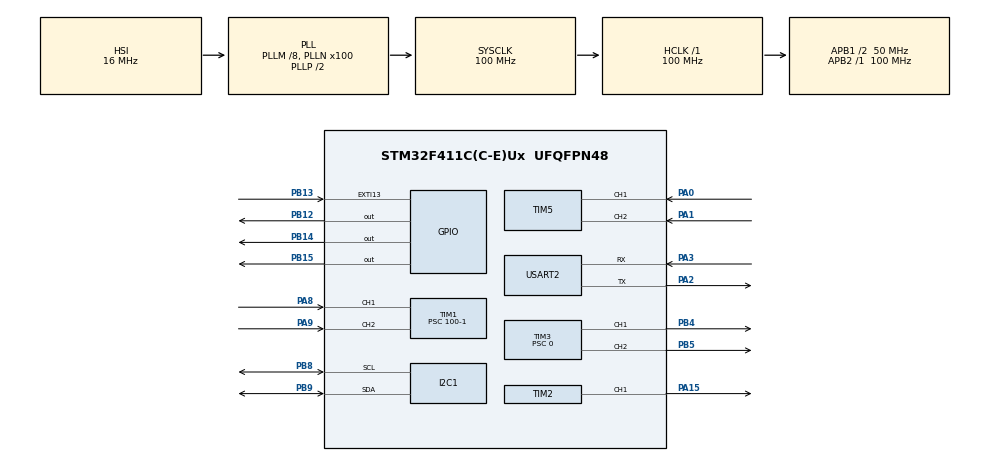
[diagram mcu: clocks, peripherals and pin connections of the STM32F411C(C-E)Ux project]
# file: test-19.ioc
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Mcu.Family=STM32F4
Mcu.Name=STM32F411C(C-E)Ux
Mcu.Package=UFQFPN48
NVIC.EXTI15_10_IRQn=true\:0\:0\:false\:false\:true\:true\:true\:true
NVIC.PriorityGroup=NVIC_PRIORITYGROUP_4
NVIC.TIM1_BRK_TIM9_IRQn=true\:0\:0\:false\:false\:true\:true\:true\:true
NVIC.TIM1_CC_IRQn=true\:0\:0\:false\:false\:true\:true\:true\:true
NVIC.TIM1_TRG_COM_TIM11_IRQn=true\:0\:0\:false\:false\:true\:true\:true\:true
NVIC.TIM1_UP_TIM10_IRQn=true\:0\:0\:false\:false\:true\:true\:true\:true
NVIC.TIM5_IRQn=true\:0\:0\:false\:false\:true\:true\:true\:true
PA0-WKUP.Signal=S_TIM5_CH1
PA1.Signal=S_TIM5_CH2
PA13.Mode=Trace_Asynchronous_SW
PA13.Signal=SYS_JTMS-SWDIO
PA14.Mode=Trace_Asynchronous_SW
PA14.Signal=SYS_JTCK-SWCLK
PA15.Signal=S_TIM2_CH1_ETR
PA2.Mode=Asynchronous
PA2.Signal=USART2_TX
PA3.Mode=Asynchronous
PA3.Signal=USART2_RX
PA8.Signal=S_TIM1_CH1
PA9.Signal=S_TIM1_CH2
PB12.Signal=GPIO_Output
PB13.Signal=GPXTI13
PB14.Signal=GPIO_Output
PB15.Signal=GPIO_Output
PB3.Mode=Trace_Asynchronous_SW
PB3.Signal=SYS_JTDO-SWO
PB4.Signal=S_TIM3_CH1
PB5.Signal=S_TIM3_CH2
PB8.Mode=I2C
PB8.Signal=I2C1_SCL
PB9.Mode=I2C
PB9.Signal=I2C1_SDA
ProjectManager.HeapSize=0x200
ProjectManager.StackSize=0x400
ProjectManager.TargetToolchain=STM32CubeIDE
RCC.48MHZClocksFreq_Value=50000000
RCC.AHBFreq_Value=100000000
RCC.APB1CLKDivider=RCC_HCLK_DIV2
RCC.APB1Freq_Value=50000000
RCC.APB1TimFreq_Value=100000000
RCC.APB2Freq_Value=100000000
RCC.APB2TimFreq_Value=100000000
RCC.CortexFreq_Value=100000000
RCC.HCLKFreq_Value=100000000
RCC.HSE_VALUE=25000000
RCC.HSI_VALUE=16000000
RCC.LSE_VALUE=32768
RCC.PLLM=8
RCC.PLLN=100
RCC.SYSCLKFreq_VALUE=100000000
RCC.SYSCLKSource=RCC_SYSCLKSOURCE_PLLCLK
RCC.VCOOutputFreq_Value=200000000
SH.S_TIM1_CH1.0=TIM1_CH1,Input_Capture1_from_TI1
SH.S_TIM1_CH2.0=TIM1_CH2,Input_Capture2_from_TI2
SH.S_TIM2_CH1_ETR.0=TIM2_CH1,PWM Generation1 CH1
SH.S_TIM3_CH1.0=TIM3_CH1,PWM Generation1 CH1
SH.S_TIM3_CH2.0=TIM3_CH2,PWM Generation2 CH2
SH.S_TIM5_CH1.0=TIM5_CH1,Encoder_Interface
SH.S_TIM5_CH2.0=TIM5_CH2,Encoder_Interface
TIM1.Channel-Input_Capture1_from_TI1=TIM_CHANNEL_1
TIM1.Channel-Input_Capture2_from_TI2=TIM_CHANNEL_2
TIM1.ICPolarity_CH1=TIM_INPUTCHANNELPOLARITY_BOTHEDGE
TIM1.ICPolarity_CH2=TIM_INPUTCHANNELPOLARITY_BOTHEDGE
TIM1.Prescaler=100-1
TIM2.Channel-PWM\ Generation1\ CH1=TIM_CHANNEL_1
TIM2.Period=5000-1
TIM3.Channel-PWM\ Generation1\ CH1=TIM_CHANNEL_1
TIM3.Channel-PWM\ Generation2\ CH2=TIM_CHANNEL_2
TIM3.Period=5000-1
TIM3.Prescaler=0
TIM5.EncoderMode=TIM_ENCODERMODE_TI12
USART2.VirtualMode=VM_ASYNC
VP_TIM1_VS_ClockSourceINT.Mode=Internal
VP_TIM2_VS_ClockSourceINT.Mode=Internal
VP_TIM3_VS_ClockSourceINT.Mode=Internal
board=custom

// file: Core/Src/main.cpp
/* USER CODE BEGIN Header */
/**
  ******************************************************************************
  * @file           : main.c
  * @brief          : Main program body
  ******************************************************************************
  * @attention
  *
  * Copyright (c) 2024 STMicroelectronics.
  * All rights reserved.
  *
  * This software is licensed under terms that can be found in the LICENSE file
  * in the root directory of this software component.
  * If no LICENSE file comes with this software, it is provided AS-IS.
  *
  ******************************************************************************
  */
/* USER CODE END Header */
#include "main.h"

/* USER CODE BEGIN Includes */
#include <stdio.h>
#include <cmath>
#include "defines.h"
#include "vl53l0x_api.h"
#include "TB6612FNG_Motor.h"
#include "RCChannel.h"
#include "RemoteControlControl.h"
#include "PololuEncoder.h"
#include "MotorControl.h"
#include "PololuServo.h"
#include "VL53L0X.h"
#include "SparkFunAPDS9960.h"
#include "ConveyorBelt.h"
#include "ColoredBlock.h"

/* USER CODE END Includes */

/* USER CODE BEGIN PD */
#define CPU_CLOCK_SPEED_MHZ 100
#define MOTOR_PWM_HZ 20000
#define RC_SIGNAL_PERIOD_US 17500
#define CONTROL_FREQUENCY_HZ 8
/* USER CODE END PD */

I2C_HandleTypeDef hi2c1;

TIM_HandleTypeDef htim1;
TIM_HandleTypeDef htim2;
TIM_HandleTypeDef htim3;
TIM_HandleTypeDef htim5;

UART_HandleTypeDef huart2;

/* USER CODE BEGIN PV */
char my_message[MESSAGE_LENGTH] = "";
int string_length;
bool initialized = false;
TB6612FNG_Motor* My_Motor;
RCChannel* ThrottleChannel;
RCChannel* SteeringChannel;
RemoteControlControl* Throttle;
RemoteControlControl* Steering;
PololuEncoder* My_Encoder;
MotorControl* My_Controller;
PololuServo* My_Servo;
//VL53L0X* My_ToF_Sensor;
VL53L0X_RangingMeasurementData_t RangingData;
VL53L0X_Dev_t vl53l0x_c; // center module
VL53L0X_DEV Dev = &vl53l0x_c;
ConveyorBelt* My_Conveyor;
SparkFun_APDS9960* My_Color_Sensor;
ColoredBlock* My_Block;
/* USER CODE END PV */

void SystemClock_Config(void);
static void MX_GPIO_Init(void);
static void MX_USART2_UART_Init(void);
static void MX_TIM2_Init(void);
static void MX_TIM5_Init(void);
static void MX_TIM1_Init(void);
static void MX_TIM3_Init(void);
static void MX_I2C1_Init(void);
/* USER CODE BEGIN PFP */
static void VL53L0X_Init(void);
void I2C_Scan(UART_HandleTypeDef* uart_handle);
/* USER CODE END PFP */

/* USER CODE BEGIN 0 */
void HAL_GPIO_EXTI_Callback(uint16_t GPIO_PIN) {
   // Your interrupt handling code here
	if(initialized)
	{
		if(GPIO_PIN == GPIO_PIN_13)
		{
			HAL_GPIO_TogglePin(GPIOB, GPIO_PIN_12);
		}
	}
}

void HAL_TIM_IC_CaptureCallback(TIM_HandleTypeDef *htim)
{
	if (initialized) // Timers must be initalized before this code can run successfully.
	{
		if((htim->Instance = TIM1))
		{
			if ( htim->Channel == HAL_TIM_ACTIVE_CHANNEL_1 )
			{
				SteeringChannel->callback();
			}

			if ( htim->Channel == HAL_TIM_ACTIVE_CHANNEL_2)
			{
				ThrottleChannel->callback();
			}
		}
	}
}

void HAL_TIM_PeriodElapsedCallback(TIM_HandleTypeDef *htim) // Not needed
{
	if (htim->Instance == TIM5)
	{
		My_Encoder->count = __HAL_TIM_GET_COUNTER(htim);
	}
}
/* USER CODE END 0 */

int main(void)
{

  /* MCU Configuration--------------------------------------------------------*/

  /* Reset of all peripherals, Initializes the Flash interface and the Systick. */
  HAL_Init();

  /* Configure the system clock */
  SystemClock_Config();

  /* Initialize all configured peripherals */
  MX_GPIO_Init();
  MX_USART2_UART_Init();
  MX_TIM2_Init();
  MX_TIM5_Init();
  MX_TIM1_Init();
  MX_TIM3_Init();
  MX_I2C1_Init();
  /* USER CODE BEGIN 2 */
  My_Motor = new TB6612FNG_Motor
		  (
		  GPIOB, GPIO_PIN_14,
		  GPIOB, GPIO_PIN_15,
		  &htim2, TIM_CHANNEL_1,
		  CPU_CLOCK_SPEED_MHZ,
		  MOTOR_PWM_HZ
		  );

  SteeringChannel = new RCChannel
		  (
		  GPIOA,
		  GPIO_PIN_8,
  		  &htim1,
  		  TIM_CHANNEL_1,
  		  RC_SIGNAL_PERIOD_US,
  		  CPU_CLOCK_SPEED_MHZ,
  		  1002,       // Calibrated full right
  		  1520,      // Calibrated neutral
  		  2035,      // Calibrated full left
  		  10000,       // New max positive
		  10000,       // New max negative (magnitude)
		  true     // Saturate if signal is over full? True by default. False good for debugging.
		  );

  ThrottleChannel = new RCChannel
		  	  	  (
		  	  	  GPIOA,
				  GPIO_PIN_9,
		  		  &htim1,
		  		  TIM_CHANNEL_2,
		  		  RC_SIGNAL_PERIOD_US,
		  		  CPU_CLOCK_SPEED_MHZ,
		  		  1056,  // Calibrated full reverse
		  		  1533,  // Calibrated neutral
		  		  2017,  // Calibrated full speed
		  		  10000,   // New max positive
				  10000,    // New max negative (magnitude)
				  true  // Saturate if signal is over full? True by default. False good for debugging.
		  	  	  );

  My_Encoder = new PololuEncoder
		  (
		  &htim5,
		  20,
		  488.3f,
		  16,
		  false // true doesn't work yet!
		  );

  My_Controller = new MotorControl
		  (
		  My_Motor,
		  My_Encoder,
		  CONTROL_FREQUENCY_HZ,
		  100.0f,
		  650.0f,
		  0.0f
		  );

  Throttle = new RemoteControlControl
		  (
		  ThrottleChannel,
		  My_Controller,
		  30
		  );

  My_Servo = new PololuServo
		  (
		  &htim3,
		  TIM_CHANNEL_1,
		  17500,
	  	  CPU_CLOCK_SPEED_MHZ,
		  60,
		  1000,
		  1500,
		  2000
		  );

//  My_ToF_Sensor = new VL53L0X
//		  (
//		  &hi2c1,
//		  0x29
//		  );

  My_Conveyor = new ConveyorBelt(My_Encoder, 38.1f);

  // Not shutdown pin for ToF_Sensor
  HAL_GPIO_WritePin(GPIOB, GPIO_PIN_10, GPIO_PIN_SET);
  VL53L0X_Init();

  // Color sensor
  My_Color_Sensor = new SparkFun_APDS9960(&hi2c1);
  //I2C_Scan(&huart2);

  My_Color_Sensor->init();
  My_Color_Sensor->disableProximitySensor();
  My_Color_Sensor->disableGestureSensor();
  My_Color_Sensor->enableLightSensor();
//  if (My_Color_Sensor->init()) {
//      int string_length = sprintf(my_message, "My_Color_Sensor-9960 initialization complete\r\n");
//      HAL_UART_Transmit(&huart2, (uint8_t *)my_message, string_length, HAL_MAX_DELAY);
//  } else {
//      int string_length = sprintf(my_message, "Something went wrong during My_Color_Sensor-9960 init!\r\n");
//      HAL_UART_Transmit(&huart2, (uint8_t *)my_message, string_length, HAL_MAX_DELAY);
//  }
//
//  I2C_Scan(&huart2);
//  if (My_Color_Sensor->disableProximitySensor()) {
//      int string_length = sprintf(my_message, "Proximity sensor disabled successfully\r\n");
//      HAL_UART_Transmit(&huart2, (uint8_t *)my_message, string_length, HAL_MAX_DELAY);
//  } else {
//      int string_length = sprintf(my_message, "Failed to disable proximity sensor\r\n");
//      HAL_UART_Transmit(&huart2, (uint8_t *)my_message, string_length, HAL_MAX_DELAY);
//  }
//
//  if (My_Color_Sensor->disableGestureSensor()) {
//      int string_length = sprintf(my_message, "Gesture sensor disabled successfully\r\n");
//      HAL_UART_Transmit(&huart2, (uint8_t *)my_message, string_length, HAL_MAX_DELAY);
//  } else {
//      int string_length = sprintf(my_message, "Failed to disable gesture sensor\r\n");
//      HAL_UART_Transmit(&huart2, (uint8_t *)my_message, string_length, HAL_MAX_DELAY);
//  }
//
//  if (My_Color_Sensor->enableLightSensor()) {
//      int string_length = sprintf(my_message, "Light sensor enabled successfully\r\n");
//      HAL_UART_Transmit(&huart2, (uint8_t *)my_message, string_length, HAL_MAX_DELAY);
//  } else {
//      int string_length = sprintf(my_message, "Failed to enable light sensor\r\n");
//      HAL_UART_Transmit(&huart2, (uint8_t *)my_message, string_length, HAL_MAX_DELAY);
//  }
//  I2C_Scan(&huart2);

  uint16_t ambient_light, red_light, green_light, blue_light;

  uint8_t task = 0; // Start on task 0
  int number_of_states = 5;

  number_of_states += 1;
  uint32_t last_tick_state[number_of_states] = {0};
  uint16_t task_frequencies[number_of_states] = {0};
  task_frequencies[1] = CONTROL_FREQUENCY_HZ; // Hz
  task_frequencies[2] = 2; // Hz
  task_frequencies[3] = 10; // Hz
  task_frequencies[4] = 2; // Hz
  uint16_t task_periods[number_of_states] = {0};

  // Loop to calculate periods based on frequencies
  for (int index = 0; index < number_of_states; index++) {
      if (task_frequencies[index] != 0) {
          task_periods[index] = 1000 / task_frequencies[index];
      } else {
          task_periods[index] = 0; // Avoid division by zero
      }
  }

  uint16_t range_reading = -1;
  uint16_t block_range_mm = 50; //Threshold
  float distance_from_ToF_to_color_sensor = 42.0f;
  bool ready_for_new_block = true;
  float first_position;
  float second_position;
  /* USER CODE END 2 */

  /* Infinite loop */
  while (1)
  {

    /* USER CODE BEGIN 3 */
	  uint32_t current_tick = HAL_GetTick();

	  switch(task)
	  {
	  	  case 0:
	  		  // Init
	  		  My_Servo->set_position(0);
	  		  HAL_Delay(300);
	  		  My_Controller->run(0);
	  		  My_Servo->set_position(0);
	  		  HAL_Delay(500);
	  		  initialized = true;

	  		  // State change
	  		  task = 1;
	  		  break;

	  	  case 1: // Motor Controller
	  		  if (current_tick - last_tick_state[1] >= task_periods[1])
	  		  {
	  			  last_tick_state[1] = current_tick;
	  			  //Throttle->update_motor();

		  		  // Set speed
		  		  My_Controller->run(-15); // RPM
	  		  }

	  		  // State change
	  		  task = 2;
	  		  break;

	  	  case 2: // ToF Sensor
			  if (current_tick - last_tick_state[2] >= task_periods[2])
			  {
				  last_tick_state[2] = current_tick;
				  //range_reading = My_ToF_Sensor->read(&huart2, true);

				  VL53L0X_PerformSingleRangingMeasurement(Dev, &RangingData);
//					if(RangingData.RangeStatus == 0) {
//						int string_length = sprintf(my_message, "Measured distance: %i\n\r", RangingData.RangeMilliMeter);
//						HAL_UART_Transmit(&huart2, (uint8_t*)my_message, string_length, HAL_MAX_DELAY);
//					} else {
//						int string_length = sprintf(my_message, "Error\r\n");
//						HAL_UART_Transmit(&huart2, (uint8_t*)my_message, string_length, HAL_MAX_DELAY);
//					}

					if(ready_for_new_block)
					{

						if(RangingData.RangeMilliMeter <= block_range_mm)
						{
							// Debug message
							int string_length = sprintf(my_message, "A block was found\r\n");
							HAL_UART_Transmit(&huart2, (uint8_t *)my_message, string_length, HAL_MAX_DELAY);

							// Store the current encoder posiiton for later.
							first_position = My_Conveyor->get_position();
							string_length = sprintf(my_message, "Block position: %.3f mm.\r\n", first_position);
							HAL_UART_Transmit(&huart2, (uint8_t *)my_message, string_length, HAL_MAX_DELAY);

							// Stop checking for blocks.
							ready_for_new_block = false;

							// Create a new block instance
							My_Block = new ColoredBlock(My_Conveyor);
						}
					}
			  }

			  // State Changes
			  task = 3;
			  break;

	  	  case 3: // Color Sensor
			  if (current_tick - last_tick_state[3] >= task_periods[3])
			  {
				  last_tick_state[3] = current_tick;

				  if (not ready_for_new_block)
				  {
					  // Debug message
					  second_position = My_Conveyor->get_position();
					  int string_length = sprintf(my_message, "Block position: %.2f mm.\r\n", fabs(second_position-first_position));
					  HAL_UART_Transmit(&huart2, (uint8_t *)my_message, string_length, HAL_MAX_DELAY);

					  if (fabs(second_position-first_position) >= distance_from_ToF_to_color_sensor)
					  {
						   // Debug message
							string_length = sprintf(my_message, "Block has reached color sensor \r\n");
							HAL_UART_Transmit(&huart2, (uint8_t *)my_message, string_length, HAL_MAX_DELAY);

						  // Update position of block
						  My_Block->update_position(My_Conveyor->get_position()-first_position);

						  // Read the color sensor
//						   My_Color_Sensor->readAmbientLight(ambient_light);
//						   My_Color_Sensor->readRedLight(red_light);
//						   My_Color_Sensor->readGreenLight(green_light);
//						   My_Color_Sensor->readBlueLight(blue_light);

							bool success = My_Color_Sensor->readAmbientLight(ambient_light) &&
										   My_Color_Sensor->readRedLight(red_light) &&
										   My_Color_Sensor->readGreenLight(green_light) &&
										   My_Color_Sensor->readBlueLight(blue_light);

							if (success) {
								int string_length = sprintf(my_message, "Ambient: %u, Red: %u, Green: %u, Blue: %u\r\n", ambient_light, red_light, green_light, blue_light);
								HAL_UART_Transmit(&huart2, (uint8_t *)my_message, string_length, HAL_MAX_DELAY);
							} else {
								int string_length = sprintf(my_message, "Error reading light values!\r\n");
								HAL_UART_Transmit(&huart2, (uint8_t *)my_message, string_length, HAL_MAX_DELAY);
							}

						  // Update the color of the block
						  My_Block->update_color(red_light >= 100);

						  // Read for new block
						  ready_for_new_block = true;

						  // Servo Position
						  if (red_light >= 100)
						  {
							  My_Servo->set_position(-35);
						  }
						  else
						  {
							  My_Servo->set_position(40);
						  }

						  // Delete object
						  delete My_Block;
					  }
				  }
	  		  }

	  		 // State changes
	  		 task = 4;
	  		 break;

	  	  case 4: // Debug messages
	  		  if (current_tick - last_tick_state[4] >= task_periods[4])
	  		  {
	  			  last_tick_state[4] = current_tick;
	  			  // My_Controller->debug_message(&huart2);
	  			  // Throttle->debug_message(&huart2);
//					bool success = My_Color_Sensor->readAmbientLight(ambient_light) &&
//								   My_Color_Sensor->readRedLight(red_light) &&
//								   My_Color_Sensor->readGreenLight(green_light) &&
//								   My_Color_Sensor->readBlueLight(blue_light);
//
//
//					if (success) {
//						int string_length = sprintf(my_message, "Ambient: %u, Red: %u, Green: %u, Blue: %u\r\n", ambient_light, red_light, green_light, blue_light);
//						HAL_UART_Transmit(&huart2, (uint8_t *)my_message, string_length, HAL_MAX_DELAY);
//					} else {
//						int string_length = sprintf(my_message, "Error reading light values!\r\n");
//						HAL_UART_Transmit(&huart2, (uint8_t *)my_message, string_length, HAL_MAX_DELAY);
//					}

	  			  // Is a block within range?
				  if (range_reading < block_range_mm)
				  {
					  sprintf(my_message, "A block is within range\r\n");
					  HAL_UART_Transmit(&huart2, (uint8_t*)my_message, MESSAGE_LENGTH, HAL_MAX_DELAY);
				  }
	  		  }

	  		  // State change
	  		  task = 1;
	  		  break;

	  	  default:
	  		  task = 0;
	  		  break;
	  }
  }
  /* USER CODE END 3 */
}

void SystemClock_Config(void)
{
  RCC_OscInitTypeDef RCC_OscInitStruct = {0};
  RCC_ClkInitTypeDef RCC_ClkInitStruct = {0};

  /** Configure the main internal regulator output voltage
  */
  __HAL_RCC_PWR_CLK_ENABLE();
  __HAL_PWR_VOLTAGESCALING_CONFIG(PWR_REGULATOR_VOLTAGE_SCALE1);

  /** Initializes the RCC Oscillators according to the specified parameters
  * in the RCC_OscInitTypeDef structure.
  */
  RCC_OscInitStruct.OscillatorType = RCC_OSCILLATORTYPE_HSI;
  RCC_OscInitStruct.HSIState = RCC_HSI_ON;
  RCC_OscInitStruct.HSICalibrationValue = RCC_HSICALIBRATION_DEFAULT;
  RCC_OscInitStruct.PLL.PLLState = RCC_PLL_ON;
  RCC_OscInitStruct.PLL.PLLSource = RCC_PLLSOURCE_HSI;
  RCC_OscInitStruct.PLL.PLLM = 8;
  RCC_OscInitStruct.PLL.PLLN = 100;
  RCC_OscInitStruct.PLL.PLLP = RCC_PLLP_DIV2;
  RCC_OscInitStruct.PLL.PLLQ = 4;
  if (HAL_RCC_OscConfig(&RCC_OscInitStruct) != HAL_OK)
  {
    Error_Handler();
  }

  /** Initializes the CPU, AHB and APB buses clocks
  */
  RCC_ClkInitStruct.ClockType = RCC_CLOCKTYPE_HCLK|RCC_CLOCKTYPE_SYSCLK
                              |RCC_CLOCKTYPE_PCLK1|RCC_CLOCKTYPE_PCLK2;
  RCC_ClkInitStruct.SYSCLKSource = RCC_SYSCLKSOURCE_PLLCLK;
  RCC_ClkInitStruct.AHBCLKDivider = RCC_SYSCLK_DIV1;
  RCC_ClkInitStruct.APB1CLKDivider = RCC_HCLK_DIV2;
  RCC_ClkInitStruct.APB2CLKDivider = RCC_HCLK_DIV1;

  if (HAL_RCC_ClockConfig(&RCC_ClkInitStruct, FLASH_LATENCY_3) != HAL_OK)
  {
    Error_Handler();
  }
}

static void MX_I2C1_Init(void)
{

  hi2c1.Instance = I2C1;
  hi2c1.Init.ClockSpeed = 100000;
  hi2c1.Init.DutyCycle = I2C_DUTYCYCLE_2;
  hi2c1.Init.OwnAddress1 = 0;
  hi2c1.Init.AddressingMode = I2C_ADDRESSINGMODE_7BIT;
  hi2c1.Init.DualAddressMode = I2C_DUALADDRESS_DISABLE;
  hi2c1.Init.OwnAddress2 = 0;
  hi2c1.Init.GeneralCallMode = I2C_GENERALCALL_DISABLE;
  hi2c1.Init.NoStretchMode = I2C_NOSTRETCH_DISABLE;
  if (HAL_I2C_Init(&hi2c1) != HAL_OK)
  {
    Error_Handler();
  }

}

static void MX_TIM1_Init(void)
{

  TIM_ClockConfigTypeDef sClockSourceConfig = {0};
  TIM_MasterConfigTypeDef sMasterConfig = {0};
  TIM_IC_InitTypeDef sConfigIC = {0};

  htim1.Instance = TIM1;
  htim1.Init.Prescaler = 100-1;
  htim1.Init.CounterMode = TIM_COUNTERMODE_UP;
  htim1.Init.Period = 65535;
  htim1.Init.ClockDivision = TIM_CLOCKDIVISION_DIV1;
  htim1.Init.RepetitionCounter = 0;
  htim1.Init.AutoReloadPreload = TIM_AUTORELOAD_PRELOAD_DISABLE;
  if (HAL_TIM_Base_Init(&htim1) != HAL_OK)
  {
    Error_Handler();
  }
  sClockSourceConfig.ClockSource = TIM_CLOCKSOURCE_INTERNAL;
  if (HAL_TIM_ConfigClockSource(&htim1, &sClockSourceConfig) != HAL_OK)
  {
    Error_Handler();
  }
  if (HAL_TIM_IC_Init(&htim1) != HAL_OK)
  {
    Error_Handler();
  }
  sMasterConfig.MasterOutputTrigger = TIM_TRGO_RESET;
  sMasterConfig.MasterSlaveMode = TIM_MASTERSLAVEMODE_DISABLE;
  if (HAL_TIMEx_MasterConfigSynchronization(&htim1, &sMasterConfig) != HAL_OK)
  {
    Error_Handler();
  }
  sConfigIC.ICPolarity = TIM_INPUTCHANNELPOLARITY_BOTHEDGE;
  sConfigIC.ICSelection = TIM_ICSELECTION_DIRECTTI;
  sConfigIC.ICPrescaler = TIM_ICPSC_DIV1;
  sConfigIC.ICFilter = 0;
  if (HAL_TIM_IC_ConfigChannel(&htim1, &sConfigIC, TIM_CHANNEL_1) != HAL_OK)
  {
    Error_Handler();
  }
  if (HAL_TIM_IC_ConfigChannel(&htim1, &sConfigIC, TIM_CHANNEL_2) != HAL_OK)
  {
    Error_Handler();
  }

}

static void MX_TIM2_Init(void)
{

  TIM_ClockConfigTypeDef sClockSourceConfig = {0};
  TIM_MasterConfigTypeDef sMasterConfig = {0};
  TIM_OC_InitTypeDef sConfigOC = {0};

  htim2.Instance = TIM2;
  htim2.Init.Prescaler = 0;
  htim2.Init.CounterMode = TIM_COUNTERMODE_UP;
  htim2.Init.Period = 5000-1;
  htim2.Init.ClockDivision = TIM_CLOCKDIVISION_DIV1;
  htim2.Init.AutoReloadPreload = TIM_AUTORELOAD_PRELOAD_DISABLE;
  if (HAL_TIM_Base_Init(&htim2) != HAL_OK)
  {
    Error_Handler();
  }
  sClockSourceConfig.ClockSource = TIM_CLOCKSOURCE_INTERNAL;
  if (HAL_TIM_ConfigClockSource(&htim2, &sClockSourceConfig) != HAL_OK)
  {
    Error_Handler();
  }
  if (HAL_TIM_PWM_Init(&htim2) != HAL_OK)
  {
    Error_Handler();
  }
  sMasterConfig.MasterOutputTrigger = TIM_TRGO_RESET;
  sMasterConfig.MasterSlaveMode = TIM_MASTERSLAVEMODE_DISABLE;
  if (HAL_TIMEx_MasterConfigSynchronization(&htim2, &sMasterConfig) != HAL_OK)
  {
    Error_Handler();
  }
  sConfigOC.OCMode = TIM_OCMODE_PWM1;
  sConfigOC.Pulse = 0;
  sConfigOC.OCPolarity = TIM_OCPOLARITY_HIGH;
  sConfigOC.OCFastMode = TIM_OCFAST_DISABLE;
  if (HAL_TIM_PWM_ConfigChannel(&htim2, &sConfigOC, TIM_CHANNEL_1) != HAL_OK)
  {
    Error_Handler();
  }
  HAL_TIM_MspPostInit(&htim2);

}

static void MX_TIM3_Init(void)
{

  TIM_ClockConfigTypeDef sClockSourceConfig = {0};
  TIM_MasterConfigTypeDef sMasterConfig = {0};
  TIM_OC_InitTypeDef sConfigOC = {0};

  htim3.Instance = TIM3;
  htim3.Init.Prescaler = 0;
  htim3.Init.CounterMode = TIM_COUNTERMODE_UP;
  htim3.Init.Period = 5000-1;
  htim3.Init.ClockDivision = TIM_CLOCKDIVISION_DIV1;
  htim3.Init.AutoReloadPreload = TIM_AUTORELOAD_PRELOAD_DISABLE;
  if (HAL_TIM_Base_Init(&htim3) != HAL_OK)
  {
    Error_Handler();
  }
  sClockSourceConfig.ClockSource = TIM_CLOCKSOURCE_INTERNAL;
  if (HAL_TIM_ConfigClockSource(&htim3, &sClockSourceConfig) != HAL_OK)
  {
    Error_Handler();
  }
  if (HAL_TIM_PWM_Init(&htim3) != HAL_OK)
  {
    Error_Handler();
  }
  sMasterConfig.MasterOutputTrigger = TIM_TRGO_RESET;
  sMasterConfig.MasterSlaveMode = TIM_MASTERSLAVEMODE_DISABLE;
  if (HAL_TIMEx_MasterConfigSynchronization(&htim3, &sMasterConfig) != HAL_OK)
  {
    Error_Handler();
  }
  sConfigOC.OCMode = TIM_OCMODE_PWM1;
  sConfigOC.Pulse = 0;
  sConfigOC.OCPolarity = TIM_OCPOLARITY_HIGH;
  sConfigOC.OCFastMode = TIM_OCFAST_DISABLE;
  if (HAL_TIM_PWM_ConfigChannel(&htim3, &sConfigOC, TIM_CHANNEL_1) != HAL_OK)
  {
    Error_Handler();
  }
  if (HAL_TIM_PWM_ConfigChannel(&htim3, &sConfigOC, TIM_CHANNEL_2) != HAL_OK)
  {
    Error_Handler();
  }
  HAL_TIM_MspPostInit(&htim3);

}

static void MX_TIM5_Init(void)
{

  TIM_Encoder_InitTypeDef sConfig = {0};
  TIM_MasterConfigTypeDef sMasterConfig = {0};

  htim5.Instance = TIM5;
  htim5.Init.Prescaler = 0;
  htim5.Init.CounterMode = TIM_COUNTERMODE_UP;
  htim5.Init.Period = 4294967295;
  htim5.Init.ClockDivision = TIM_CLOCKDIVISION_DIV1;
  htim5.Init.AutoReloadPreload = TIM_AUTORELOAD_PRELOAD_DISABLE;
  sConfig.EncoderMode = TIM_ENCODERMODE_TI12;
  sConfig.IC1Polarity = TIM_ICPOLARITY_RISING;
  sConfig.IC1Selection = TIM_ICSELECTION_DIRECTTI;
  sConfig.IC1Prescaler = TIM_ICPSC_DIV1;
  sConfig.IC1Filter = 0;
  sConfig.IC2Polarity = TIM_ICPOLARITY_RISING;
  sConfig.IC2Selection = TIM_ICSELECTION_DIRECTTI;
  sConfig.IC2Prescaler = TIM_ICPSC_DIV1;
  sConfig.IC2Filter = 0;
  if (HAL_TIM_Encoder_Init(&htim5, &sConfig) != HAL_OK)
  {
    Error_Handler();
  }
  sMasterConfig.MasterOutputTrigger = TIM_TRGO_RESET;
  sMasterConfig.MasterSlaveMode = TIM_MASTERSLAVEMODE_DISABLE;
  if (HAL_TIMEx_MasterConfigSynchronization(&htim5, &sMasterConfig) != HAL_OK)
  {
    Error_Handler();
  }

}

static void MX_USART2_UART_Init(void)
{

  huart2.Instance = USART2;
  huart2.Init.BaudRate = 115200;
  huart2.Init.WordLength = UART_WORDLENGTH_8B;
  huart2.Init.StopBits = UART_STOPBITS_1;
  huart2.Init.Parity = UART_PARITY_NONE;
  huart2.Init.Mode = UART_MODE_TX_RX;
  huart2.Init.HwFlowCtl = UART_HWCONTROL_NONE;
  huart2.Init.OverSampling = UART_OVERSAMPLING_16;
  if (HAL_UART_Init(&huart2) != HAL_OK)
  {
    Error_Handler();
  }

}

static void MX_GPIO_Init(void)
{
  GPIO_InitTypeDef GPIO_InitStruct = {0};

  /* GPIO Ports Clock Enable */
  __HAL_RCC_GPIOA_CLK_ENABLE();
  __HAL_RCC_GPIOB_CLK_ENABLE();

  /*Configure GPIO pin Output Level */
  HAL_GPIO_WritePin(GPIOB, GPIO_PIN_10|GPIO_PIN_12|GPIO_PIN_14|GPIO_PIN_15, GPIO_PIN_RESET);

  /*Configure GPIO pins : PB10 PB12 PB14 PB15 */
  GPIO_InitStruct.Pin = GPIO_PIN_10|GPIO_PIN_12|GPIO_PIN_14|GPIO_PIN_15;
  GPIO_InitStruct.Mode = GPIO_MODE_OUTPUT_PP;
  GPIO_InitStruct.Pull = GPIO_NOPULL;
  GPIO_InitStruct.Speed = GPIO_SPEED_FREQ_LOW;
  HAL_GPIO_Init(GPIOB, &GPIO_InitStruct);

  /*Configure GPIO pin : PB13 */
  GPIO_InitStruct.Pin = GPIO_PIN_13;
  GPIO_InitStruct.Mode = GPIO_MODE_IT_RISING;
  GPIO_InitStruct.Pull = GPIO_NOPULL;
  HAL_GPIO_Init(GPIOB, &GPIO_InitStruct);

  /* EXTI interrupt init*/
  HAL_NVIC_SetPriority(EXTI15_10_IRQn, 0, 0);
  HAL_NVIC_EnableIRQ(EXTI15_10_IRQn);

}

/* USER CODE BEGIN 4 */
void I2C_Scan(UART_HandleTypeDef* uart_handle) {

	// Start
    sprintf(my_message, "Scanning...\r\n");
    HAL_UART_Transmit(uart_handle, (uint8_t*)my_message, strlen(my_message), HAL_MAX_DELAY);

    // Find
    for (uint8_t i = 1; i < 128; i++)
    {
        HAL_StatusTypeDef result = HAL_I2C_IsDeviceReady(&hi2c1, (uint16_t)(i << 1), 1, 10);
        if (result == HAL_OK) {
            snprintf(my_message, sizeof(my_message), "Device found at address 0x%02X\r\n", i);
            HAL_UART_Transmit(&huart2, (uint8_t*)my_message, strlen(my_message), HAL_MAX_DELAY);
        }
    }

    // Finsish
    sprintf(my_message, "Done.\r\n\r\n");
    HAL_UART_Transmit(&huart2, (uint8_t*) my_message, strlen(my_message), HAL_MAX_DELAY);
    HAL_Delay(1000); // Unnecessary
}

// VL53L0X time-of-flight sensor initialization
static void VL53L0X_Init(void) {
	uint32_t refSpadCount;
	uint8_t isApertureSpads;
	uint8_t VhvSettings;
	uint8_t PhaseCal;

	Dev->I2cHandle = &hi2c1;
	Dev->I2cDevAddr = 0x29 << 1;

	VL53L0X_WaitDeviceBooted(Dev);
	VL53L0X_DataInit(Dev);
	VL53L0X_StaticInit(Dev);
	VL53L0X_PerformRefCalibration(Dev, &VhvSettings, &PhaseCal);
	VL53L0X_PerformRefSpadManagement(Dev, &refSpadCount, &isApertureSpads);
	VL53L0X_SetDeviceMode(Dev, VL53L0X_DEVICEMODE_SINGLE_RANGING);

	VL53L0X_SetLimitCheckEnable(Dev, VL53L0X_CHECKENABLE_SIGMA_FINAL_RANGE, 1);
	VL53L0X_SetLimitCheckEnable(Dev, VL53L0X_CHECKENABLE_SIGNAL_RATE_FINAL_RANGE, 1);
	VL53L0X_SetLimitCheckValue(Dev, VL53L0X_CHECKENABLE_SIGNAL_RATE_FINAL_RANGE, (FixPoint1616_t) (0.1*65536));
	VL53L0X_SetLimitCheckValue(Dev, VL53L0X_CHECKENABLE_SIGMA_FINAL_RANGE, (FixPoint1616_t) (60*65536));
	VL53L0X_SetMeasurementTimingBudgetMicroSeconds(Dev, 33000);
	VL53L0X_SetVcselPulsePeriod(Dev, VL53L0X_VCSEL_PERIOD_PRE_RANGE, 18);
	VL53L0X_SetVcselPulsePeriod(Dev, VL53L0X_VCSEL_PERIOD_FINAL_RANGE, 14);
}

/* USER CODE END 4 */

void Error_Handler(void)
{
  __disable_irq();
  while (1)
  {
  }
}
